# STM32G563xx register map
File version: 1.0
Registers are 32-bit, read-write, reset 0x0 unless marked. A register's access mark holds for its fields unless they carry their own. Offsets are from the block's base; [hi:lo] are bit positions; {n}, {i} and the like mark numbered series; 'fields as' and 'values as' point back to an identical list.

## GPIOA — General-purpose I/Os (GPIO)
Base 0x46000000
Same registers: GPIOB 0x46000400, GPIOC 0x46000800, GPIOD 0x46000C00, GPIOE 0x46001000, GPIOF 0x46001400, GPIOG 0x46001800, GPIOH 0x46001C00
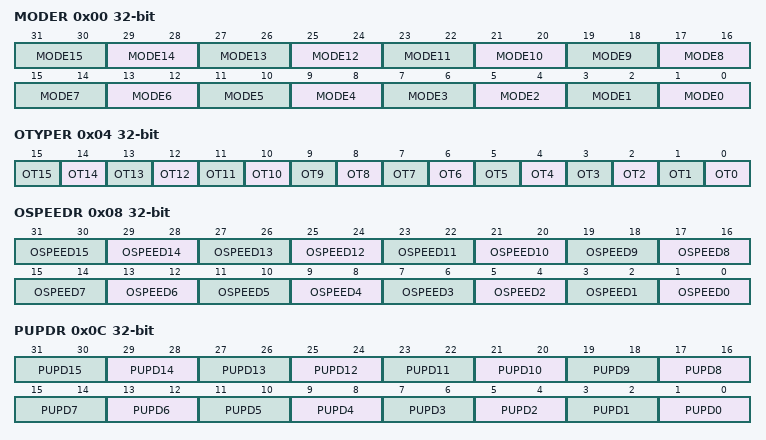
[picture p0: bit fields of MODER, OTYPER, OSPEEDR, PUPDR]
0x00 MODER — GPIO port mode register
  [2n+1:2n] MODE{n} (n=0..15) — Port x configuration I/O pin y
0x04 OTYPER — GPIO port output type register
  [n] OT{n} (n=0..15) — Port x configuration I/O pin y
0x08 OSPEEDR — GPIO port output speed register
  [2n+1:2n] OSPEED{n} (n=0..15) — Port x configuration I/O pin y
0x0C PUPDR — GPIO port pull-up/pull-down register
  [2n+1:2n] PUPD{n} (n=0..15) — Port x configuration I/O pin y
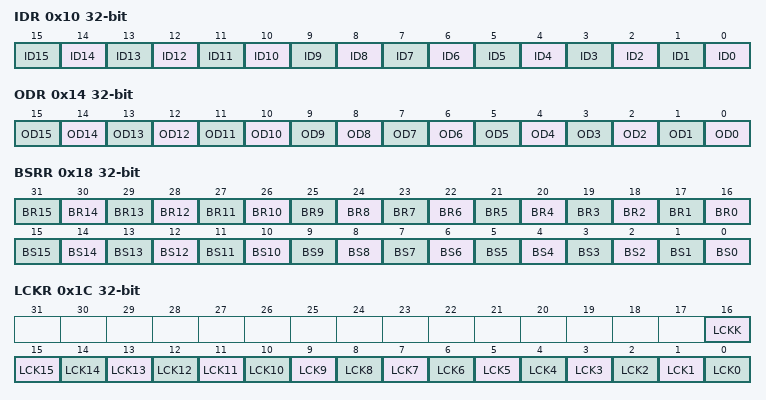
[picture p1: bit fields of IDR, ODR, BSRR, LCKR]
0x10 IDR ro — GPIO port input data register
  [n] ID{n} (n=0..15) — Port x input data I/O pin y
0x14 ODR — GPIO port output data register
  [n] OD{n} (n=0..15) — Port output data I/O pin y
0x18 BSRR — GPIO port bit set/reset register
  [n+16] BR{n} (n=0..15) — Port x reset I/O pin y
  [n] BS{n} (n=0..15) — Port x set I/O pin y
0x1C LCKR — GPIO port configuration lock register
  [16] LCKK — Lock key
  [n] LCK{n} (n=0..15) — Port x lock I/O pin y
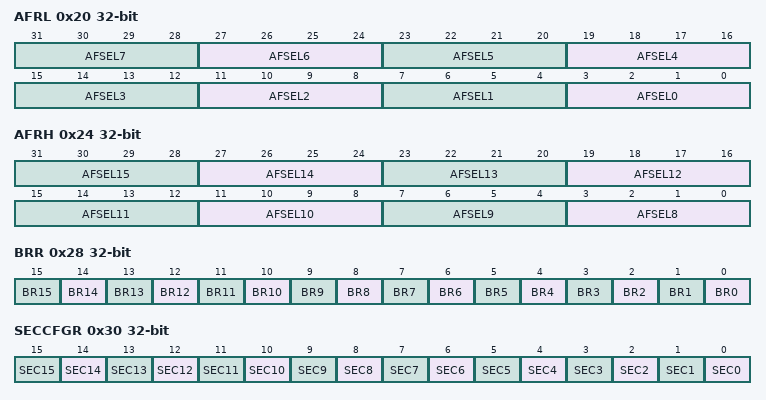
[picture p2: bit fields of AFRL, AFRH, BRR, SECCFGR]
0x20 AFRL — GPIO alternate function low register
  [4n+3:4n] AFSEL{n} (n=0..7)
0x24 AFRH — GPIO alternate function low register
  [4n-29:4n-32] AFSEL{n} (n=8..15)
0x28 BRR — GPIO port bit reset register
  [n] BR{n} (n=0..15) — Port x reset IO pin y
0x30 SECCFGR — GPIO secure configuration register
  [n] SEC{n} (n=0..15) — I/O pin of Port x secure bit enable y

## OTFDEC1
Base 0x46005000
0x00 CR — OTFDEC control register
  [0] ENC
0x10 PRIVCFGR — OTFDEC privileged access control configuration register
  [0] PRIV
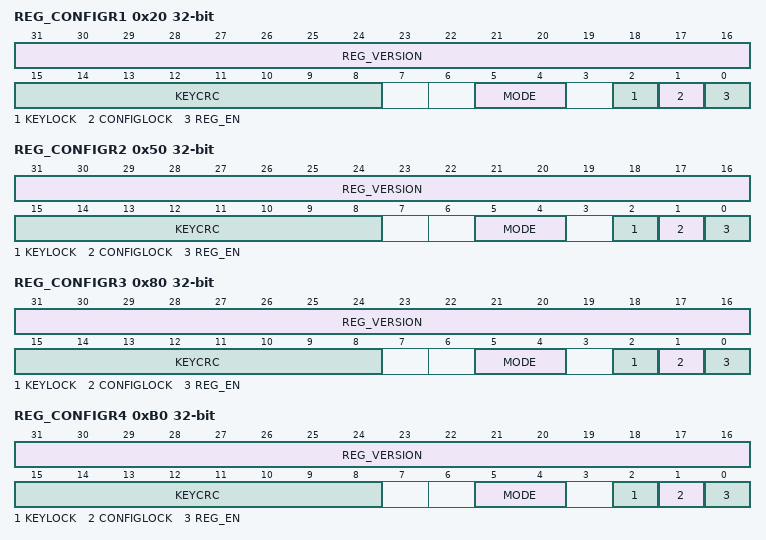
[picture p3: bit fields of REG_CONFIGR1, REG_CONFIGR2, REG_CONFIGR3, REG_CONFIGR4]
0x20 REG_CONFIGR1 — OTFDEC Region Configuration register
  [31:16] REG_VERSION
  [15:8] KEYCRC
  [5:4] MODE — operating mode
  [2] KEYLOCK
  [1] CONFIGLOCK
  [0] REG_EN
0x24 REG_START_ADDR1 — OTFDEC Region Start Address register
  [31:0] REG_START_ADDR
0x28 REG_END_ADDR1 — OTFDEC Region End Address register
  [31:0] REG_END_ADDR
0x2C REG_NONCER01 — OTFDEC Region Nonce register 0
  [31:0] REG_NONCE
0x30 REG_NONCER1 — OTFDEC Region Nonce register 1
  [31:0] REG_NONCE
0x34 REG_KEYR01 — OTFDEC Region Key register 0
  [31:0] REG_KEY
0x38 REG_KEYR1 — OTFDEC Region Key register 1
  [31:0] REG_KEY
0x3C REG_KEYR21 — OTFDEC Region Key register 2
  [31:0] REG_KEY
0x40 REG_KEYR31 — OTFDEC Region Key register 3
  [31:0] REG_KEY
0x50 REG_CONFIGR2 — OTFDEC Region Configuration register
  fields as REG_CONFIGR1
0x54 REG_START_ADDR2 — OTFDEC Region Start Address register
  [31:0] REG_START_ADDR
0x58 REG_END_ADDR2 — OTFDEC Region End Address register
  [31:0] REG_END_ADDR
0x5C REG_NONCER02 — OTFDEC Region Nonce register 0
  [31:0] REG_NONCE
0x60 REG_NONCER12 — OTFDEC Region Nonce register 1
  [31:0] REG_NONCE
0x64 REG_KEYR02 — OTFDEC Region Key register 0
  [31:0] REG_KEY
0x68 REG_KEYR12 — OTFDEC Region Key register 1
  [31:0] REG_KEY
0x6C REG_KEYR2 — OTFDEC Region Key register 2
  [31:0] REG_KEY
0x70 REG_KEYR32 — OTFDEC Region Key register 3
  [31:0] REG_KEY
0x80 REG_CONFIGR3 — OTFDEC Region Configuration register
  fields as REG_CONFIGR1
0x84 REG_START_ADDR3 — OTFDEC Region Start Address register
  [31:0] REG_START_ADDR
0x88 REG_END_ADDR3 — OTFDEC Region End Address register
  [31:0] REG_END_ADDR
0x8C REG_NONCER03 — OTFDEC Region Nonce register 0
  [31:0] REG_NONCE
0x90 REG_NONCER13 — OTFDEC Region Nonce register 1
  [31:0] REG_NONCE
0x94 REG_KEYR03 — OTFDEC Region Key register 0
  [31:0] REG_KEY
0x98 REG_KEYR13 — OTFDEC Region Key register 1
  [31:0] REG_KEY
0x9C REG_KEYR23 — OTFDEC Region Key register 2
  [31:0] REG_KEY
0xA0 REG_KEYR3 — OTFDEC Region Key register 3
  [31:0] REG_KEY
0xB0 REG_CONFIGR4 — OTFDEC Region Configuration register
  fields as REG_CONFIGR1
0xB4 REG_START_ADDR4 — OTFDEC Region Start Address register
  [31:0] REG_START_ADDR
0xB8 REG_END_ADDR4 — OTFDEC Region End Address register
  [31:0] REG_END_ADDR
0xBC REG_NONCER04 — OTFDEC Region Nonce register 0
  [31:0] REG_NONCE
0xC0 REG_NONCER14 — OTFDEC Region Nonce register 1
  [31:0] REG_NONCE
0xC4 REG_KEYR04 — OTFDEC Region Key register 0
  [31:0] REG_KEY
0xC8 REG_KEYR14 — OTFDEC Region Key register 1
  [31:0] REG_KEY
0xCC REG_KEYR24 — OTFDEC Region Key register 2
  [31:0] REG_KEY
0xD0 REG_KEYR34 — OTFDEC Region Key register 3
  [31:0] REG_KEY
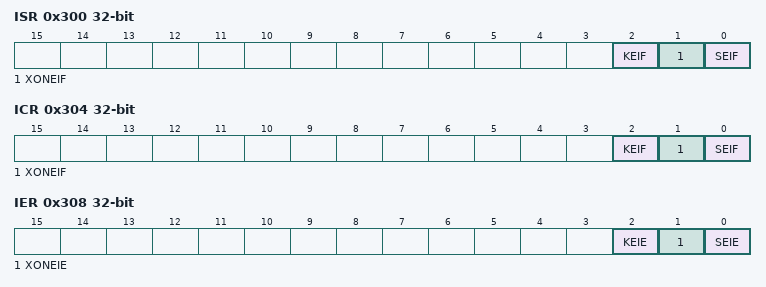
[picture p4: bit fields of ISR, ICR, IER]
0x300 ISR ro — OTFDEC interrupt status register
  [2] KEIF, [1] XONEIF, [0] SEIF
0x304 ICR — OTFDEC interrupt clear register
  [2] KEIF, [1] XONEIF, [0] SEIF
0x308 IER — OTFDEC interrupt enable register
  [2] KEIE, [1] XONEIE, [0] SEIE
